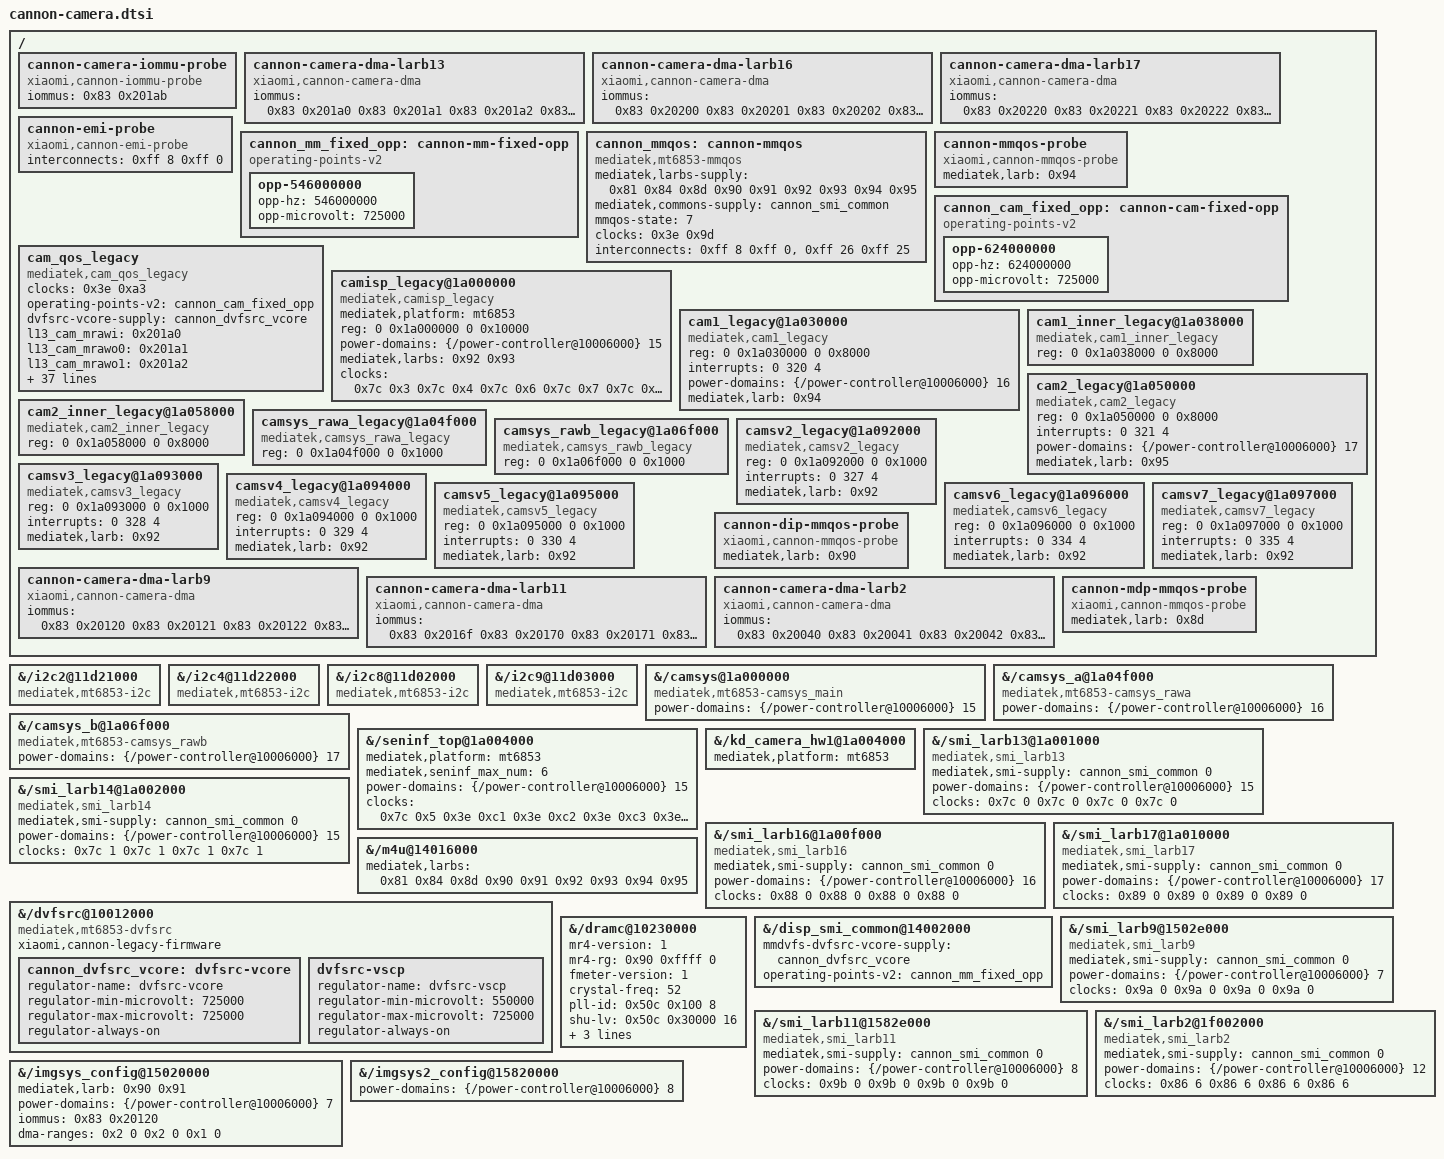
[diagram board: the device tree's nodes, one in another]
// SPDX-License-Identifier: GPL-2.0-only
// Original Cannon clock specifiers, with native camera genpd and providers.
&{/i2c2@11d21000} {
 compatible = "mediatek,mt6853-i2c";
};
&{/i2c4@11d22000} {
 compatible = "mediatek,mt6853-i2c";
};
&{/i2c8@11d02000} {
 compatible = "mediatek,mt6853-i2c";
};
&{/i2c9@11d03000} {
 compatible = "mediatek,mt6853-i2c";
};
&{/camsys@1a000000} {
 compatible = "mediatek,mt6853-camsys_main";
 power-domains = <&{/power-controller@10006000} 15>;
};
&{/camsys_a@1a04f000} {
 compatible = "mediatek,mt6853-camsys_rawa";
 power-domains = <&{/power-controller@10006000} 16>;
};
&{/camsys_b@1a06f000} {
 compatible = "mediatek,mt6853-camsys_rawb";
 power-domains = <&{/power-controller@10006000} 17>;
};
&{/seninf_top@1a004000} {
 mediatek,platform = "mt6853";
 mediatek,seninf_max_num = "6";
 power-domains = <&{/power-controller@10006000} 15>;
 clocks = <0x7c 0x5 0x3e 0xc1 0x3e 0xc2 0x3e 0xc3 0x3e 0xad 0x3e 0xae 0x3e 0xaf 0x3e 0xb0 0x3e 0xb1 0x3e 0x56 0x3e 0x17 0x3e 0x29 0x3e 0x16 0x3e 0x57 0x3e 0x18 0x3e 0x19 0x3e 0x3 0x3e 0x21 0x3e 0xa3>;
 clock-names = "CAMSYS_SENINF_CGPDN", "TOP_MUX_SENINF", "TOP_MUX_SENINF1", "TOP_MUX_SENINF2", "TOP_MUX_CAMTG", "TOP_MUX_CAMTG2", "TOP_MUX_CAMTG3", "TOP_MUX_CAMTG4", "TOP_MUX_CAMTG5", "TOP_CLK26M", "TOP_UNIVP_192M_D8", "TOP_UNIVPLL_D6_D8", "TOP_UNIVP_192M_D4", "TOP_F26M_CK_D2", "TOP_UNIVP_192M_D16", "TOP_UNIVP_192M_D32", "TOP_UNIVP_D4_D2", "TOP_MAINP_D5", "cannon-isp";
};
&{/kd_camera_hw1@1a004000} {
 mediatek,platform = "mt6853";
};

&{/smi_larb13@1a001000} {
 compatible = "mediatek,smi_larb13", "mediatek,mt6853-smi-larb", "mediatek,smi-larb";
 mediatek,smi-supply = <&cannon_smi_common 0>;
 power-domains = <&{/power-controller@10006000} 15>;
 clocks = <0x7c 0 0x7c 0 0x7c 0 0x7c 0>;
 clock-names = "apb", "smi", "gals0", "gals1";
};

&{/smi_larb14@1a002000} {
 compatible = "mediatek,smi_larb14", "mediatek,mt6853-smi-larb", "mediatek,smi-larb";
 mediatek,smi-supply = <&cannon_smi_common 0>;
 power-domains = <&{/power-controller@10006000} 15>;
 clocks = <0x7c 1 0x7c 1 0x7c 1 0x7c 1>;
 clock-names = "apb", "smi", "gals0", "gals1";
};

&{/smi_larb16@1a00f000} {
 compatible = "mediatek,smi_larb16", "mediatek,mt6853-smi-larb", "mediatek,smi-larb";
 mediatek,smi-supply = <&cannon_smi_common 0>;
 power-domains = <&{/power-controller@10006000} 16>;
 clocks = <0x88 0 0x88 0 0x88 0 0x88 0>;
 clock-names = "apb", "smi", "gals0", "gals1";
};

&{/smi_larb17@1a010000} {
 compatible = "mediatek,smi_larb17", "mediatek,mt6853-smi-larb", "mediatek,smi-larb";
 mediatek,smi-supply = <&cannon_smi_common 0>;
 power-domains = <&{/power-controller@10006000} 17>;
 clocks = <0x89 0 0x89 0 0x89 0 0x89 0>;
 clock-names = "apb", "smi", "gals0", "gals1";
};

&{/m4u@14016000} {
 mediatek,larbs = <0x81 0x84 0x8d 0x90 0x91 0x92 0x93 0x94 0x95>;
};

// CAM fake port only: validate the real 8-12 GiB CAM DMA domain without
// submitting a frame or assigning a live RAW/CAMSV port to a diagnostic.
/ {
 cannon-camera-iommu-probe {
  compatible = "xiaomi,cannon-iommu-probe";
  iommus = <0x83 0x201ab>;
 };
};

// Native IOMMU permits one LARB per DMA client. All three share CAM domain 2.
/ {
 cannon-camera-dma-larb13 {
  compatible = "xiaomi,cannon-camera-dma";
  iommus = <0x83 0x201a0 0x83 0x201a1 0x83 0x201a2 0x83 0x201a3 0x83 0x201a4 0x83 0x201a5 0x83 0x201a6 0x83 0x201a7 0x83 0x201a8>;
 };
 cannon-camera-dma-larb16 {
  compatible = "xiaomi,cannon-camera-dma";
  iommus = <0x83 0x20200 0x83 0x20201 0x83 0x20202 0x83 0x20203 0x83 0x20204 0x83 0x20205 0x83 0x20206 0x83 0x20207 0x83 0x20208 0x83 0x20209 0x83 0x2020a 0x83 0x2020b 0x83 0x2020c 0x83 0x2020d 0x83 0x2020e 0x83 0x2020f 0x83 0x20210>;
 };
 cannon-camera-dma-larb17 {
  compatible = "xiaomi,cannon-camera-dma";
  iommus = <0x83 0x20220 0x83 0x20221 0x83 0x20222 0x83 0x20223 0x83 0x20224 0x83 0x20225 0x83 0x20226 0x83 0x20227 0x83 0x20228 0x83 0x20229 0x83 0x2022a 0x83 0x2022b 0x83 0x2022c 0x83 0x2022d 0x83 0x2022e 0x83 0x2022f 0x83 0x20230>;
 };
};

&{/dvfsrc@10012000} {
 compatible = "mediatek,mt6853-dvfsrc";
 reg-names = "dvfsrc", "spm";
 xiaomi,cannon-legacy-firmware;
 #interconnect-cells = <1>;
 cannon_dvfsrc_vcore: dvfsrc-vcore {
  regulator-name = "dvfsrc-vcore";
  // LK CAM624/display546 clocks remain fixed during bringup.
  regulator-min-microvolt = <725000>;
  regulator-max-microvolt = <725000>;
  regulator-always-on;
 };
 dvfsrc-vscp {
  regulator-name = "dvfsrc-vscp";
  regulator-min-microvolt = <550000>;
  regulator-max-microvolt = <725000>;
  regulator-always-on;
 };
};

/ {
 cannon-emi-probe {
  compatible = "xiaomi,cannon-emi-probe";
  interconnects = <0xff 8 0xff 0>;
  interconnect-names = "icc-bw";
 };
};

// Keep legacy underscore properties for LK; add native DRAMC spellings.
&{/dramc@10230000} {
 mr4-version = <1>;
 mr4-rg = <0x90 0xffff 0>;
 fmeter-version = <1>;
 crystal-freq = <52>;
 pll-id = <0x50c 0x100 8>;
 shu-lv = <0x50c 0x30000 16>;
 shu-of = <0x700>;
 pll-md = <0x744 0x100 8 0x744 0x100 8>;
 ckdiv4-ca = <0xb74 4 2 0xb74 4 2>;
};
&{/disp_smi_common@14002000} {
 mmdvfs-dvfsrc-vcore-supply = <&cannon_dvfsrc_vcore>;
 operating-points-v2 = <&cannon_mm_fixed_opp>;
};
/ {
 cannon_mm_fixed_opp: cannon-mm-fixed-opp {
  compatible = "operating-points-v2";
  opp-546000000 {
   opp-hz = /bits/ 64 <546000000>;
   opp-microvolt = <725000>;
  };
 };
 cannon_mmqos: cannon-mmqos {
  compatible = "mediatek,mt6853-mmqos";
  #mtk-interconnect-cells = <1>;
  mediatek,larbs-supply = <0x81 0x84 0x8d 0x90 0x91 0x92 0x93 0x94 0x95>;
  mediatek,commons-supply = <&cannon_smi_common>;
  mmqos-state = <7>;
  clocks = <0x3e 0x9d>;
  clock-names = "mm";
  interconnects = <0xff 8 0xff 0>, <0xff 26 0xff 25>;
  interconnect-names = "icc-bw", "icc-hrt-bw";
 };
};

/ {
 cannon-mmqos-probe {
  compatible = "xiaomi,cannon-mmqos-probe";
  mediatek,larb = <0x94>;
 };
};

/ {
 cannon_cam_fixed_opp: cannon-cam-fixed-opp {
  compatible = "operating-points-v2";
  opp-624000000 { opp-hz = /bits/ 64 <624000000>; opp-microvolt = <725000>; };
 };
		cam_qos_legacy {
			/* non-v4l2 legacy camera */
			compatible = "mediatek,cam_qos_legacy";
			clocks = <0x3e 0xa3>;
			clock-names = "cannon-isp";
			operating-points-v2 = <&cannon_cam_fixed_opp>;
			dvfsrc-vcore-supply = <&cannon_dvfsrc_vcore>;

			l13_cam_mrawi = <0x201a0>;
			l13_cam_mrawo0 = <0x201a1>;
			l13_cam_mrawo1 = <0x201a2>;
			l13_cam_camsv4 = <0x201a6>;
			l13_cam_camsv5 = <0x201a7>;
			l13_cam_camsv6 = <0x201a8>;

			l16_cam_imgo_r1_a = <0x20200>;
			l16_cam_rrzo_r1_a = <0x20201>;
			l16_cam_cqi_r1_a = <0x20202>;
			l16_cam_bpci_r1_a = <0x20203>;
			l16_cam_yuvo_r1_a = <0x20204>;
			l16_cam_ufdi_r2_a = <0x20205>;
			l16_cam_rawi_r2_a = <0x20206>;
			l16_cam_rawi_r3_a = <0x20207>;
			l16_cam_aao_r1_a = <0x20208>;
			l16_cam_afo_r1_a = <0x20209>;
			l16_cam_flko_r1_a = <0x2020a>;
			l16_cam_lceso_r1_a = <0x2020b>;
			l16_cam_crzo_r1_a = <0x2020c>;
			l16_cam_ltmso_r1_a = <0x2020d>;
			l16_cam_rsso_r1_a = <0x2020e>;
			l16_cam_aaho_r1_a = <0x2020f>;
			l16_cam_lsci_r1_a = <0x20210>;

			l17_cam_imgo_r1_b = <0x20220>;
			l17_cam_rrzo_r1_b = <0x20221>;
			l17_cam_cqi_r1_b = <0x20222>;
			l17_cam_bpci_r1_b = <0x20223>;
			l17_cam_yuvo_r1_b = <0x20224>;
			l17_cam_ufdi_r2_b = <0x20225>;
			l17_cam_rawi_r2_b = <0x20226>;
			l17_cam_rawi_r3_b = <0x20227>;
			l17_cam_aao_r1_b = <0x20228>;
			l17_cam_afo_r1_b = <0x20229>;
			l17_cam_flko_r1_b = <0x2022a>;
			l17_cam_lceso_r1_b = <0x2022b>;
			l17_cam_crzo_r1_b = <0x2022c>;
			l17_cam_ltmso_r1_b = <0x2022d>;
			l17_cam_rsso_r1_b = <0x2022e>;
			l17_cam_aaho_r1_b = <0x2022f>;
			l17_cam_lsci_r1_b = <0x20230>;
		};
 camisp_legacy@1a000000 {
  compatible = "mediatek,camisp_legacy";
  mediatek,platform = "mt6853";
  reg = <0 0x1a000000 0 0x10000>;
  power-domains = <&{/power-controller@10006000} 15>;
  mediatek,larbs = <0x92 0x93>;
  clocks = <0x7c 0x3 0x7c 0x4 0x7c 0x6 0x7c 0x7 0x7c 0x8 0x7c 0x0 0x7c 0x1 0x7c 0x9 0x7c 0x5 0x7c 0xf 0x88 0x0 0x88 0x1 0x88 0x2 0x89 0x0 0x89 0x1 0x89 0x2 0x3e 0xa4 0x3e 0xcf>;
  clock-names = "CAMSYS_CAM_CGPDN", "CAMSYS_CAMTG_CGPDN", "CAMSYS_CAMSV1_CGPDN", "CAMSYS_CAMSV2_CGPDN", "CAMSYS_CAMSV3_CGPDN", "CAMSYS_LARB13_CGPDN", "CAMSYS_LARB14_CGPDN", "CAMSYS_CCU0_CGPDN", "CAMSYS_SENINF_CGPDN", "CAMSYS_MAIN_CAM2MM_GALS_CGPDN", "CAMSYS_RAWALARB16_CGPDN", "CAMSYS_RAWACAM_CGPDN", "CAMSYS_RAWATG_CGPDN", "CAMSYS_RAWBLARB17_CGPDN", "CAMSYS_RAWBCAM_CGPDN", "CAMSYS_RAWBTG_CGPDN", "TOPCKGEN_TOP_MUX_CCU", "TOPCKGEN_TOP_MUX_CAMTM";
 };
 cam1_legacy@1a030000 { compatible = "mediatek,cam1_legacy"; reg = <0 0x1a030000 0 0x8000>; interrupts = <0 320 4>; power-domains = <&{/power-controller@10006000} 16>; mediatek,larb = <0x94>; };
 cam1_inner_legacy@1a038000 { compatible = "mediatek,cam1_inner_legacy"; reg = <0 0x1a038000 0 0x8000>; };
 cam2_legacy@1a050000 { compatible = "mediatek,cam2_legacy"; reg = <0 0x1a050000 0 0x8000>; interrupts = <0 321 4>; power-domains = <&{/power-controller@10006000} 17>; mediatek,larb = <0x95>; };
 cam2_inner_legacy@1a058000 { compatible = "mediatek,cam2_inner_legacy"; reg = <0 0x1a058000 0 0x8000>; };
 camsys_rawa_legacy@1a04f000 { compatible = "mediatek,camsys_rawa_legacy"; reg = <0 0x1a04f000 0 0x1000>; };
 camsys_rawb_legacy@1a06f000 { compatible = "mediatek,camsys_rawb_legacy"; reg = <0 0x1a06f000 0 0x1000>; };
 camsv2_legacy@1a092000 { compatible = "mediatek,camsv2_legacy"; reg = <0 0x1a092000 0 0x1000>; interrupts = <0 327 4>; mediatek,larb = <0x92>; };
 camsv3_legacy@1a093000 { compatible = "mediatek,camsv3_legacy"; reg = <0 0x1a093000 0 0x1000>; interrupts = <0 328 4>; mediatek,larb = <0x92>; };
 camsv4_legacy@1a094000 { compatible = "mediatek,camsv4_legacy"; reg = <0 0x1a094000 0 0x1000>; interrupts = <0 329 4>; mediatek,larb = <0x92>; };
 camsv5_legacy@1a095000 { compatible = "mediatek,camsv5_legacy"; reg = <0 0x1a095000 0 0x1000>; interrupts = <0 330 4>; mediatek,larb = <0x92>; };
 camsv6_legacy@1a096000 { compatible = "mediatek,camsv6_legacy"; reg = <0 0x1a096000 0 0x1000>; interrupts = <0 334 4>; mediatek,larb = <0x92>; };
 camsv7_legacy@1a097000 { compatible = "mediatek,camsv7_legacy"; reg = <0 0x1a097000 0 0x1000>; interrupts = <0 335 4>; mediatek,larb = <0x92>; };
};

// DIP/WPE/MFB use the same translated 8-12 GiB domain as RAW/CAMSV.
// SCPSYS consumes IMG gates to power ISP domains: the clock providers must
// remain independent of these domains, matching the native MT6853 bindings.
// Runtime power is owned by the SMI LARBs and their DMA consumers.
&{/smi_larb9@1502e000} {
 compatible = "mediatek,smi_larb9", "mediatek,mt6853-smi-larb", "mediatek,smi-larb";
 mediatek,smi-supply = <&cannon_smi_common 0>;
 power-domains = <&{/power-controller@10006000} 7>;
 clocks = <0x9a 0 0x9a 0 0x9a 0 0x9a 0>;
 clock-names = "apb", "smi", "gals0", "gals1";
};
&{/smi_larb11@1582e000} {
 compatible = "mediatek,smi_larb11", "mediatek,mt6853-smi-larb", "mediatek,smi-larb";
 mediatek,smi-supply = <&cannon_smi_common 0>;
 power-domains = <&{/power-controller@10006000} 8>;
 clocks = <0x9b 0 0x9b 0 0x9b 0 0x9b 0>;
 clock-names = "apb", "smi", "gals0", "gals1";
};
/ {
 cannon-camera-dma-larb9 {
  compatible = "xiaomi,cannon-camera-dma";
  iommus = <0x83 0x20120 0x83 0x20121 0x83 0x20122 0x83 0x20123 0x83 0x20124 0x83 0x20125 0x83 0x20126 0x83 0x20127 0x83 0x20128 0x83 0x20129 0x83 0x2012a 0x83 0x2012b 0x83 0x2012c 0x83 0x2012d 0x83 0x2012e 0x83 0x2012f 0x83 0x20130 0x83 0x20131 0x83 0x20132 0x83 0x20133 0x83 0x20134 0x83 0x20135 0x83 0x20136 0x83 0x20137 0x83 0x20138 0x83 0x20139>;
 };
 cannon-camera-dma-larb11 {
  compatible = "xiaomi,cannon-camera-dma";
  iommus = <0x83 0x2016f 0x83 0x20170 0x83 0x20171 0x83 0x20172 0x83 0x20173 0x83 0x20174 0x83 0x20175 0x83 0x20176 0x83 0x20177 0x83 0x20178 0x83 0x20179>;
 };
 cannon-dip-mmqos-probe { compatible = "xiaomi,cannon-mmqos-probe"; mediatek,larb = <0x90>; };
};

// MT6853 MDP RDMA/WROT use LARB2 in CAM domain 2, not the display domain.
&{/smi_larb2@1f002000} {
 compatible = "mediatek,smi_larb2", "mediatek,mt6853-smi-larb", "mediatek,smi-larb";
 mediatek,smi-supply = <&cannon_smi_common 0>;
 power-domains = <&{/power-controller@10006000} 12>;
 clocks = <0x86 6 0x86 6 0x86 6 0x86 6>;
 clock-names = "apb", "smi", "gals0", "gals1";
};
/ {
 cannon-camera-dma-larb2 {
  compatible = "xiaomi,cannon-camera-dma";
  iommus = <0x83 0x20040 0x83 0x20041 0x83 0x20042 0x83 0x20043>;
 };
 cannon-mdp-mmqos-probe {
  compatible = "xiaomi,cannon-mmqos-probe";
  mediatek,larb = <0x8d>;
 };
};

// Native ISP6s DIP frontend. Keep overlapping CCF providers unchanged.
&{/imgsys_config@15020000} {
 mediatek,larb = <0x90 0x91>;
 power-domains = <&{/power-controller@10006000} 7>;
 iommus = <0x83 0x20120>;
 dma-ranges = <0x2 0 0x2 0 0x1 0>;
};
&{/imgsys2_config@15820000} {
 power-domains = <&{/power-controller@10006000} 8>;
};
// The stock Cannon IRQs are SPI 501 (MSS) and SPI 500 (MSF).
// Only the DIP_A frame IRQ (SPI 346) is consumed by this native frontend.
